/* LIN DESCRIPTION FILE */
/* Date: 09.11.2021 */
/* Project: ARRIVAL */
/* Author: Matthias Wullich */
/* BCS Automotive Interface Solutions GmbH */
/* History */
/* 09.11.2021 V1.0 */

LIN_description_file;
LIN_protocol_version = "2.0";
LIN_language_version = "2.0";
LIN_speed = 19.2 kbps;

Nodes {
  Master: CIO2, 10 ms, 0.1 ms ;
  Slaves: RLS ;
}

Signals {
  Master_Cnt: 4, 0, CIO2, RLS ;
  Cranking: 1, 0, CIO2, RLS ;
  Wiper_Sns: 3, 0, CIO2, RLS ;
  Wiper_Auto: 1, 0, CIO2, RLS ;
  Wiper_Wash: 1, 0, CIO2, RLS ;
  Wiper_Park: 1, 1, CIO2, RLS ;
  Vehicle_Speed: 8, 254, CIO2, RLS ;
  RLS_Cnt: 4, 0, RLS, CIO2 ;
  RLS_ResponseError: 1, 0, RLS, CIO2 ;
  RLS_Valid: 1, 0, RLS, CIO2 ;
  RLS_LsHeadlampOn: 1, 0, RLS, CIO2 ;
  RLS_LsSwitchReason: 5, 0, RLS, CIO2 ;
  RLS_LsError: 1, 0, RLS, CIO2 ;
  RLS_LsGlobal: 10, 1022, RLS, CIO2 ;
  RLS_LsForward: 10, 1022, RLS, CIO2 ;
  RLS_RsWiperspeed: 2, 0, RLS, CIO2 ;
  RLS_RsSplash: 1, 0, RLS, CIO2 ;
  RLS_RsError: 1, 0, RLS, CIO2 ;
  RLS_HsScreenTemp: 8, 254, RLS, CIO2 ;
  RLS_HsDewPoint: 8, 254, RLS, CIO2 ;
  RLS_HsHumidity: 8, 254, RLS, CIO2 ;
  RLS_SsLeft: 8, 254, RLS, CIO2 ;
  RLS_SsRight: 8, 254, RLS, CIO2 ;
}

Frames {
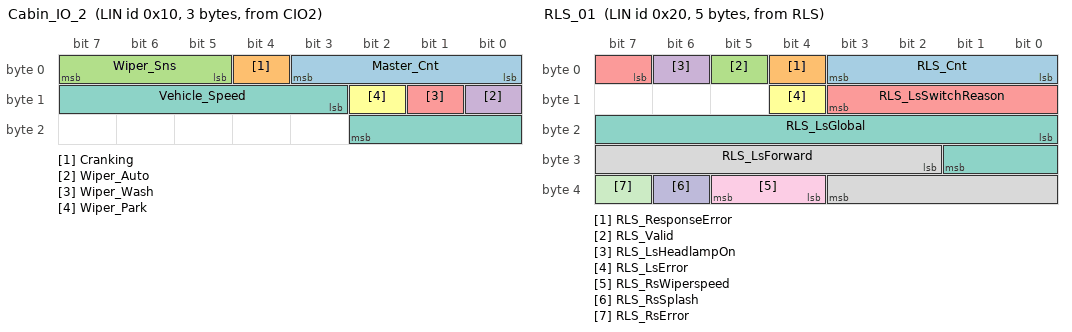
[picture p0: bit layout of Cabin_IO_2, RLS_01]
  Cabin_IO_2: 0x10, CIO2, 3 {
    Master_Cnt, 0 ;
    Cranking, 4 ;
    Wiper_Sns, 5 ;
    Wiper_Auto, 8 ;
    Wiper_Wash, 9 ;
    Wiper_Park, 10 ;
    Vehicle_Speed, 11 ;

  }
  RLS_01: 0x20, RLS, 5 {
    RLS_Cnt, 0 ;
    RLS_ResponseError, 4 ;
    RLS_Valid, 5 ;
    RLS_LsHeadlampOn, 6 ;
    RLS_LsSwitchReason, 7 ;
    RLS_LsError, 12 ;
    RLS_LsGlobal, 16 ;
    RLS_LsForward, 26 ;
    RLS_RsWiperspeed, 36 ;
    RLS_RsSplash, 38 ;
    RLS_RsError, 39 ;
  }
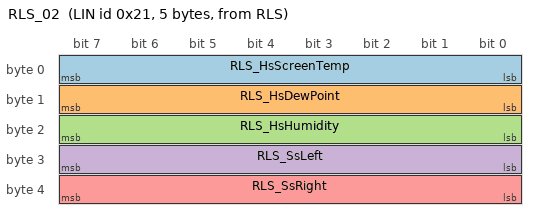
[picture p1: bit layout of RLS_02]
  RLS_02: 0x21, RLS, 5 {
    RLS_HsScreenTemp, 0 ;
    RLS_HsDewPoint, 8 ;
    RLS_HsHumidity, 16 ;
    RLS_SsLeft, 24 ;
    RLS_SsRight, 32 ;
  }
}

Node_attributes {
  RLS{
    LIN_protocol = "2.0" ;
    configured_NAD = 0x01 ;
    product_id = 0x00E2, 0x0, 0 ;
    response_error = RLS_ResponseError ;
    P2_min = 10 ms ;
    ST_min = 10 ms ;
    configurable_frames {
      Cabin_IO_2 = 0x1001 ;
      RLS_01 = 0x1002 ;
    RLS_02 = 0x1003 ;
    }
  }
}

Schedule_tables {
 BCS_RLS_main {
    Cabin_IO_2 delay 10 ms ;
    RLS_01 delay 10 ms ;
  RLS_02 delay 10 ms ;
  }
}

Signal_encoding_types {
  cranking_encoding {
    logical_value, 0, "not cranking" ;
    logical_value, 1, "cranking" ;
  }
  sns_encoding{
    logical_value, 0, "very low sensitivity" ;
    logical_value, 1, "low sensitivity" ;
  logical_value, 2, "medium sensitivity" ;
  logical_value, 3, "high sensitivity" ;
  logical_value, 4, "very high sensitivity" ;
  }
  auto_encoding {
    logical_value, 0, "off" ;
    logical_value, 1, "auto mode" ;
  }
  wash_encoding {
    logical_value, 0, "washing inactive" ;
    logical_value, 1, "washing active" ;
  }
  park_encoding {
    logical_value, 0, "outside park position" ;
    logical_value, 1, "in park position" ;
  }
  vehicle_speed_encoding {
    physical_value, 0, 253, 1, 0, "km/h" ;
    logical_value, 254, "init" ;
    logical_value, 255, "error" ;
  }
  error_encoding {
    logical_value, 0, "no error" ;
    logical_value, 1, "error" ;
  }
  valid_encoding {
    logical_value, 0, "not vaild" ;
    logical_value, 1, "valid data" ;
  }
  headlamp_encoding {
    logical_value, 0, "off" ;
    logical_value, 1, "on" ;
  }
  switchReason_encoding {
    logical_value, 0, "off" ;
    logical_value, 1, "dusk" ;
  logical_value, 2, "tunnel" ;
  logical_value, 4, "garage" ;
  logical_value, 8, "rain" ;
  logical_value, 16, "speed" ;
  }
  brightness_encoding {
    physical_value, 0, 1000, 25, 0, "lux" ;
    logical_value, 1022, "init" ;
    logical_value, 1023, "error" ;
  }
  wiperspeed_encoding {
    logical_value, 0, "off" ;
    logical_value, 1, "low speed" ;
  logical_value, 2, "high speed" ;
  }
  splash_encoding {
    logical_value, 0, "no splash" ;
    logical_value, 1, "splash" ;
  }
  temperature_encoding {
    physical_value, 0, 240, 0.5, -20, "Degree Celsius" ;
    logical_value, 254, "init" ;
    logical_value, 255, "error" ;
  }
  humidity_encoding {
    physical_value, 0, 200, 0.5, 0, "%" ;
    logical_value, 254, "init" ;
    logical_value, 255, "error" ;
  }
  solar_encoding{
    physical_value, 0, 240, 5, 0, "W/m2" ;
    logical_value, 254, "init" ;
    logical_value, 255, "error" ;
  }
}

Signal_representation {
  cranking_encoding: Cranking ;
  sns_encoding: Wiper_Sns ;
  auto_encoding: Wiper_Auto ;
  wash_encoding: Wiper_Wash ;
  park_encoding: Wiper_Park ;
  vehicle_speed_encoding: Vehicle_Speed ;
  error_encoding: RLS_ResponseError, RLS_LsError, RLS_RsError ;
  valid_encoding: RLS_Valid ;
  headlamp_encoding: RLS_LsHeadlampOn ;
  switchReason_encoding: RLS_LsSwitchReason ;
  brightness_encoding: RLS_LsGlobal, RLS_LsForward ;
  wiperspeed_encoding: RLS_RsWiperspeed ;
  splash_encoding: RLS_RsSplash ;
  temperature_encoding: RLS_HsScreenTemp, RLS_HsDewPoint ;
  humidity_encoding: RLS_HsHumidity ;
  solar_encoding: RLS_SsLeft, RLS_SsRight ;
}
